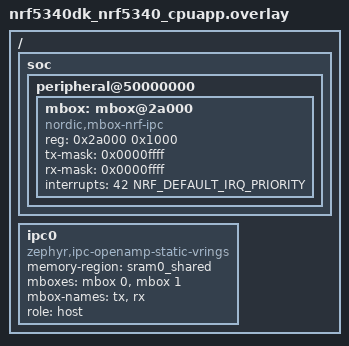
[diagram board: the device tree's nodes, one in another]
/*
 * Copyright (c) 2022 Nordic Semiconductor ASA
 *
 * SPDX-License-Identifier: LicenseRef-Nordic-5-Clause
 */

/ {
	soc {
		peripheral@50000000 {
			/delete-node/ ipc@2a000;

			mbox: mbox@2a000 {
				compatible = "nordic,mbox-nrf-ipc";
				reg = <0x2a000 0x1000>;
				tx-mask = <0x0000ffff>;
				rx-mask = <0x0000ffff>;
				interrupts = <42 NRF_DEFAULT_IRQ_PRIORITY>;
				#mbox-cells = <1>;
				status = "okay";
			};
		};
	};

	ipc0: ipc0 {
		compatible = "zephyr,ipc-openamp-static-vrings";
		memory-region = <&sram0_shared>;
		mboxes = <&mbox 0>, <&mbox 1>;
		mbox-names = "tx", "rx";
		role = "host";
		status = "okay";
	};
};
